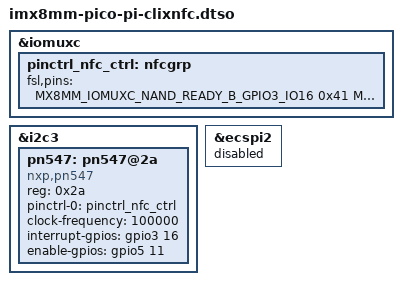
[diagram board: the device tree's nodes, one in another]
// SPDX-License-Identifier: (GPL-2.0 OR MIT)
/*
 * Copyright 2020 TechNexion Ltd.
 *
 * Author: Richard Hu <richard.hu@technexion.com>
 *         Ray Chang <ray.chang@technexion.com>
 *
 */

/dts-v1/;
/plugin/;

#include <dt-bindings/interrupt-controller/irq.h>
#include <dt-bindings/gpio/gpio.h>
#include "../imx8mm-pinfunc.h"

&iomuxc {
	pinctrl-names = "default";

	pinctrl_nfc_ctrl: nfcgrp {
		fsl,pins = <
			MX8MM_IOMUXC_NAND_READY_B_GPIO3_IO16 0x41	/* PIN_INT, GPIO_P26 */
			MX8MM_IOMUXC_ECSPI2_MOSI_GPIO5_IO11	0x41	/* PIN_ENABLE */
		>;
	};
};

&i2c3 {
	status = "okay";
	#address-cells = <1>;
	#size-cells = <0>;

	pn547: pn547@2a {
		compatible = "nxp,pn547";
		reg = <0x2a>;
		pinctrl-names = "default";
		pinctrl-0 = <&pinctrl_nfc_ctrl>;
		clock-frequency = <100000>;
		interrupt-gpios = <&gpio3 16 0>;
		enable-gpios = <&gpio5 11 0>;
		status = "okay";
	};
};

&ecspi2 {
	status = "disabled";
};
